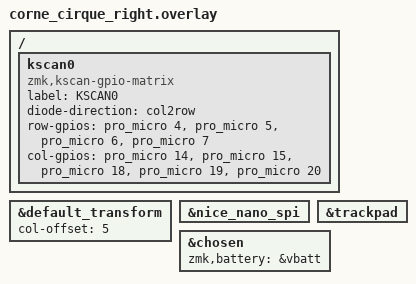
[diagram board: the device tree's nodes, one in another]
/*
 * Copyright (c) 2020 Pete Johanson
 *
 * SPDX-License-Identifier: MIT
 */

#include "corne_cirque.dtsi"

&default_transform {
	col-offset = <5>;
};

/ {
	kscan0: kscan0 {
		compatible = "zmk,kscan-gpio-matrix";
		label = "KSCAN0";

		diode-direction = "col2row";
		row-gpios
			= <&pro_micro 4 (GPIO_ACTIVE_HIGH | GPIO_PULL_DOWN)>
			, <&pro_micro 5 (GPIO_ACTIVE_HIGH | GPIO_PULL_DOWN)>
			, <&pro_micro 6 (GPIO_ACTIVE_HIGH | GPIO_PULL_DOWN)>
			, <&pro_micro 7 (GPIO_ACTIVE_HIGH | GPIO_PULL_DOWN)>
			;
		col-gpios
			= <&pro_micro 14 GPIO_ACTIVE_HIGH>
			, <&pro_micro 15 GPIO_ACTIVE_HIGH>
			, <&pro_micro 18 GPIO_ACTIVE_HIGH>
			, <&pro_micro 19 GPIO_ACTIVE_HIGH>
			, <&pro_micro 20 GPIO_ACTIVE_HIGH>
			;
	};
};

&nice_nano_spi {
    status = "okay";
};

&trackpad {
    status = "okay";
};

&chosen {
    zmk,battery = &vbatt;
};
